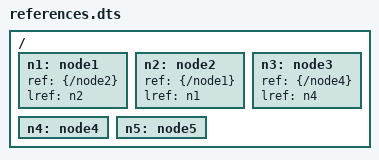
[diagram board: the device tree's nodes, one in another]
/dts-v1/;

/ {
	/* Explicit phandles */
	n1: node1 {
		linux,phandle = <0x2000>;
		ref = <&{/node2}>; /* reference precedes target */
		lref = <&n2>;
	};
	n2: node2 {
		phandle = <0x1>;
		ref = <&{/node1}>; /* reference after target */
		lref = <&n1>;
	};

	/* Implicit phandles */
	n3: node3 {
		ref = <&{/node4}>;
		lref = <&n4>;
	};
	n4: node4 {
	};

	/* Explicit phandle with implicit value */
	/* This self-reference is the standard way to tag a node as requiring
	 * a phandle (perhaps for reference by nodes that will be dynamically
	 * added) without explicitly allocating it a phandle.
	 * The self-reference requires some special internal handling, though
	 * so check it actually works */
	n5: node5 {
		linux,phandle = <&n5>;
		phandle = <&n5>;
	};
};
